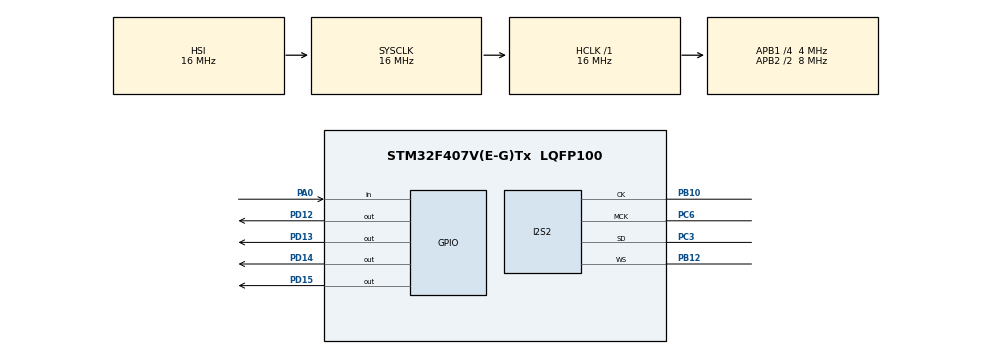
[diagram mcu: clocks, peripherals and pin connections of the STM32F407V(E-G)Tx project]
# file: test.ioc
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Dma.Request0=SPI2_TX
Dma.SPI2_TX.0.Direction=DMA_MEMORY_TO_PERIPH
Dma.SPI2_TX.0.FIFOMode=DMA_FIFOMODE_DISABLE
Dma.SPI2_TX.0.Instance=DMA1_Stream4
Dma.SPI2_TX.0.MemDataAlignment=DMA_MDATAALIGN_HALFWORD
Dma.SPI2_TX.0.MemInc=DMA_MINC_ENABLE
Dma.SPI2_TX.0.Mode=DMA_CIRCULAR
Dma.SPI2_TX.0.PeriphDataAlignment=DMA_PDATAALIGN_HALFWORD
Dma.SPI2_TX.0.PeriphInc=DMA_PINC_DISABLE
Dma.SPI2_TX.0.Priority=DMA_PRIORITY_HIGH
I2S2.AudioFreq=I2S_AUDIOFREQ_192K
I2S2.ErrorAudioFreq=-2.34 %
I2S2.FullDuplexMode=I2S_FULLDUPLEXMODE_DISABLE
I2S2.Instance=SPI$Index
I2S2.RealAudioFreq=187.5 KHz
I2S2.VirtualMode=I2S_MODE_MASTER
Mcu.Family=STM32F4
Mcu.Name=STM32F407V(E-G)Tx
Mcu.Package=LQFP100
NVIC.DMA1_Stream4_IRQn=true\:0\:0\:false\:false\:true\:false\:true\:true
NVIC.PriorityGroup=NVIC_PRIORITYGROUP_4
PA0-WKUP.GPIO_PuPd=GPIO_NOPULL
PA0-WKUP.Signal=GPIO_Input
PB10.Mode=Half_Duplex_Master
PB10.Signal=I2S2_CK
PB12.Mode=Half_Duplex_Master
PB12.Signal=I2S2_WS
PC3.Mode=Half_Duplex_Master
PC3.Signal=I2S2_SD
PC6.Mode=Master_Clock_Activated
PC6.Signal=I2S2_MCK
PD12.Signal=GPIO_Output
PD13.Signal=GPIO_Output
PD14.Signal=GPIO_Output
PD15.Signal=GPIO_Output
ProjectManager.HeapSize=0x200
ProjectManager.StackSize=0x400
ProjectManager.TargetToolchain=STM32CubeIDE
RCC.48MHZClocksFreq_Value=168000000
RCC.AHBFreq_Value=16000000
RCC.APB1CLKDivider=RCC_HCLK_DIV4
RCC.APB1Freq_Value=4000000
RCC.APB1TimFreq_Value=8000000
RCC.APB2CLKDivider=RCC_HCLK_DIV2
RCC.APB2Freq_Value=8000000
RCC.APB2TimFreq_Value=16000000
RCC.CortexFreq_Value=16000000
RCC.HCLKFreq_Value=16000000
RCC.HSE_VALUE=25000000
RCC.HSI_VALUE=16000000
RCC.LSE_VALUE=32768
RCC.PLLM=8
RCC.PLLN=336
RCC.SYSCLKFreq_VALUE=16000000
RCC.VCOOutputFreq_Value=672000000
board=custom

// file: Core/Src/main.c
/* USER CODE BEGIN Header */
/**
  ******************************************************************************
  * @file           : main.c
  * @brief          : Main program body
  ******************************************************************************
  * @attention
  *
  * Copyright (c) 2025 STMicroelectronics.
  * All rights reserved.
  *
  * This software is licensed under terms that can be found in the LICENSE file
  * in the root directory of this software component.
  * If no LICENSE file comes with this software, it is provided AS-IS.
  *
  ******************************************************************************
  */
/* USER CODE END Header */
#include "main.h"

/* USER CODE BEGIN Includes */
#include "led.h"
#include "ADC.h"
/* USER CODE END Includes */

I2S_HandleTypeDef hi2s2;
DMA_HandleTypeDef hdma_spi2_tx;

void SystemClock_Config(void);
static void MX_GPIO_Init(void);
static void MX_DMA_Init(void);
static void MX_I2S2_Init(void);

int main(void)
{

  /* MCU Configuration--------------------------------------------------------*/

  /* Reset of all peripherals, Initializes the Flash interface and the Systick. */
  HAL_Init();

  /* Configure the system clock */
  SystemClock_Config();

  /* Initialize all configured peripherals */
  MX_GPIO_Init();
  MX_DMA_Init();
  MX_I2S2_Init();

  /* Infinite loop */
  while (1)
  {

    /* USER CODE BEGIN 3 */

//	  blinking();
//	  rotate(100,50);
	  fire_mask();

  }
  /* USER CODE END 3 */
}

void SystemClock_Config(void)
{
  RCC_OscInitTypeDef RCC_OscInitStruct = {0};
  RCC_ClkInitTypeDef RCC_ClkInitStruct = {0};

  /** Macro to configure the PLL multiplication factor
  */
  __HAL_RCC_PLL_PLLM_CONFIG(8);

  /** Macro to configure the PLL clock source
  */
  __HAL_RCC_PLL_PLLSOURCE_CONFIG(RCC_PLLSOURCE_HSI);

  /** Configure the main internal regulator output voltage
  */
  __HAL_RCC_PWR_CLK_ENABLE();
  __HAL_PWR_VOLTAGESCALING_CONFIG(PWR_REGULATOR_VOLTAGE_SCALE1);

  /** Initializes the RCC Oscillators according to the specified parameters
  * in the RCC_OscInitTypeDef structure.
  */
  RCC_OscInitStruct.OscillatorType = RCC_OSCILLATORTYPE_HSI;
  RCC_OscInitStruct.HSIState = RCC_HSI_ON;
  RCC_OscInitStruct.HSICalibrationValue = RCC_HSICALIBRATION_DEFAULT;
  RCC_OscInitStruct.PLL.PLLState = RCC_PLL_NONE;
  RCC_OscInitStruct.PLL.PLLSource = RCC_PLLSOURCE_HSI;
  if (HAL_RCC_OscConfig(&RCC_OscInitStruct) != HAL_OK)
  {
    Error_Handler();
  }

  /** Initializes the CPU, AHB and APB buses clocks
  */
  RCC_ClkInitStruct.ClockType = RCC_CLOCKTYPE_HCLK|RCC_CLOCKTYPE_SYSCLK
                              |RCC_CLOCKTYPE_PCLK1|RCC_CLOCKTYPE_PCLK2;
  RCC_ClkInitStruct.SYSCLKSource = RCC_SYSCLKSOURCE_HSI;
  RCC_ClkInitStruct.AHBCLKDivider = RCC_SYSCLK_DIV1;
  RCC_ClkInitStruct.APB1CLKDivider = RCC_HCLK_DIV4;
  RCC_ClkInitStruct.APB2CLKDivider = RCC_HCLK_DIV2;

  if (HAL_RCC_ClockConfig(&RCC_ClkInitStruct, FLASH_LATENCY_0) != HAL_OK)
  {
    Error_Handler();
  }
}

static void MX_I2S2_Init(void)
{

  hi2s2.Instance = SPI2;
  hi2s2.Init.Mode = I2S_MODE_MASTER_TX;
  hi2s2.Init.Standard = I2S_STANDARD_PHILIPS;
  hi2s2.Init.DataFormat = I2S_DATAFORMAT_16B;
  hi2s2.Init.MCLKOutput = I2S_MCLKOUTPUT_ENABLE;
  hi2s2.Init.AudioFreq = I2S_AUDIOFREQ_192K;
  hi2s2.Init.CPOL = I2S_CPOL_LOW;
  hi2s2.Init.ClockSource = I2S_CLOCK_PLL;
  hi2s2.Init.FullDuplexMode = I2S_FULLDUPLEXMODE_DISABLE;
  if (HAL_I2S_Init(&hi2s2) != HAL_OK)
  {
    Error_Handler();
  }

}

static void MX_DMA_Init(void)
{

  /* DMA controller clock enable */
  __HAL_RCC_DMA1_CLK_ENABLE();

  /* DMA interrupt init */
  /* DMA1_Stream4_IRQn interrupt configuration */
  HAL_NVIC_SetPriority(DMA1_Stream4_IRQn, 0, 0);
  HAL_NVIC_EnableIRQ(DMA1_Stream4_IRQn);

}

static void MX_GPIO_Init(void)
{
  GPIO_InitTypeDef GPIO_InitStruct = {0};

  /* GPIO Ports Clock Enable */
  __HAL_RCC_GPIOC_CLK_ENABLE();
  __HAL_RCC_GPIOA_CLK_ENABLE();
  __HAL_RCC_GPIOB_CLK_ENABLE();
  __HAL_RCC_GPIOD_CLK_ENABLE();

  /*Configure GPIO pin Output Level */
  HAL_GPIO_WritePin(GPIOD, GPIO_PIN_12|GPIO_PIN_13|GPIO_PIN_14|GPIO_PIN_15, GPIO_PIN_RESET);

  /*Configure GPIO pin : PA0 */
  GPIO_InitStruct.Pin = GPIO_PIN_0;
  GPIO_InitStruct.Mode = GPIO_MODE_INPUT;
  GPIO_InitStruct.Pull = GPIO_NOPULL;
  HAL_GPIO_Init(GPIOA, &GPIO_InitStruct);

  /*Configure GPIO pins : PD12 PD13 PD14 PD15 */
  GPIO_InitStruct.Pin = GPIO_PIN_12|GPIO_PIN_13|GPIO_PIN_14|GPIO_PIN_15;
  GPIO_InitStruct.Mode = GPIO_MODE_OUTPUT_PP;
  GPIO_InitStruct.Pull = GPIO_NOPULL;
  GPIO_InitStruct.Speed = GPIO_SPEED_FREQ_LOW;
  HAL_GPIO_Init(GPIOD, &GPIO_InitStruct);

}

void Error_Handler(void)
{
  __disable_irq();
  while (1)
  {
  }
}
